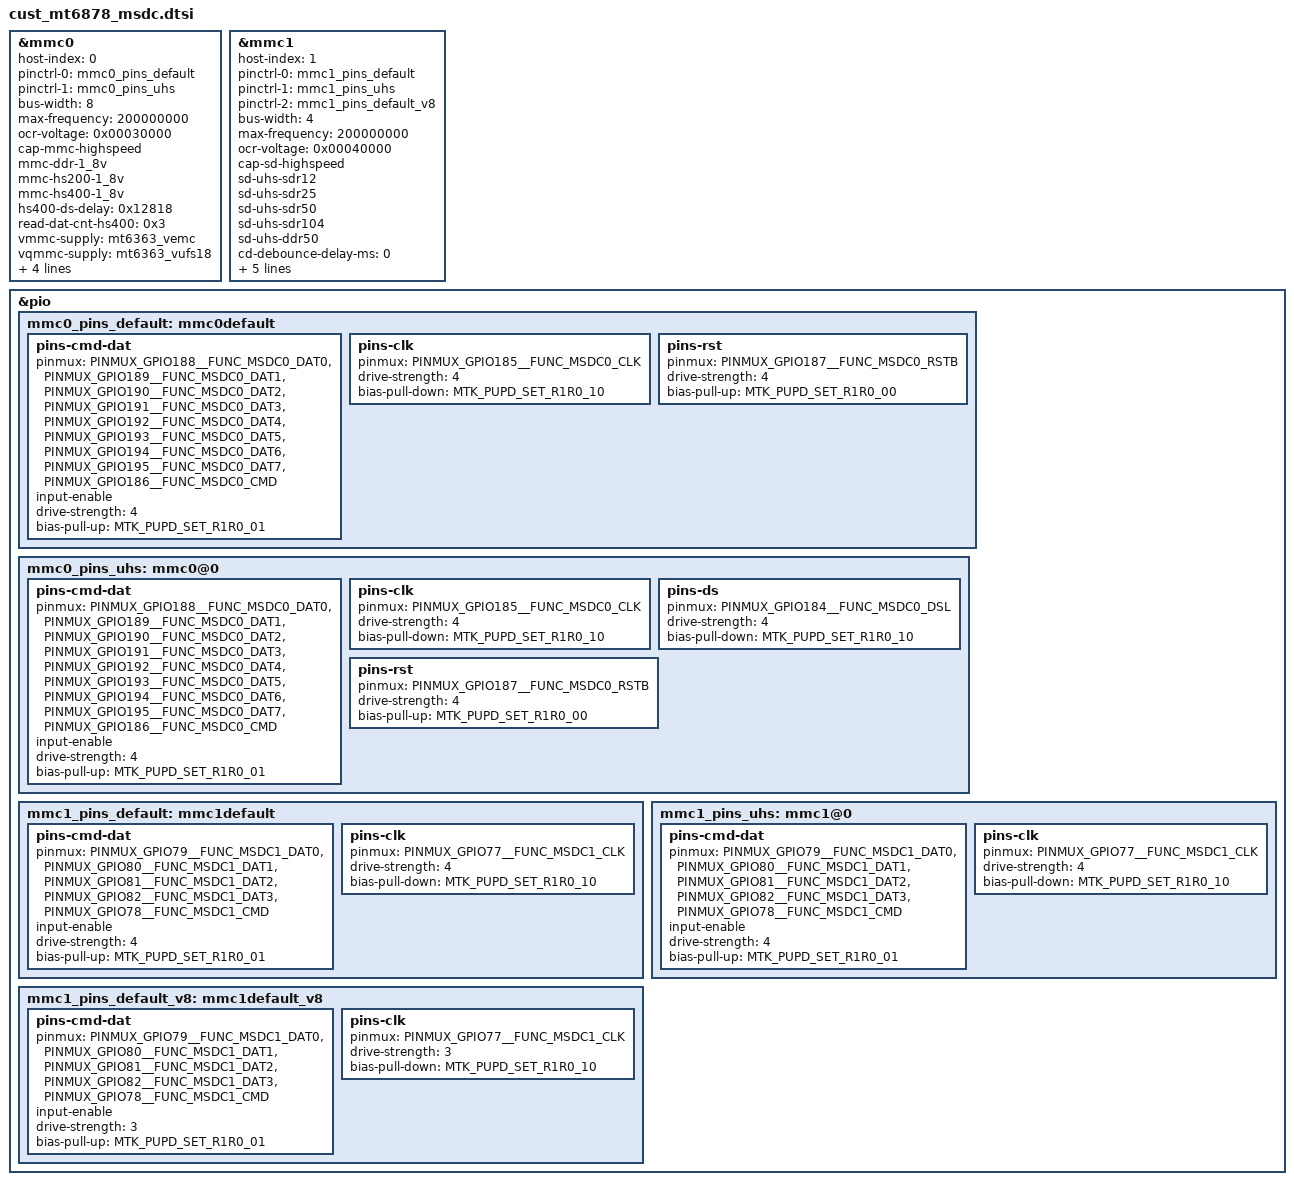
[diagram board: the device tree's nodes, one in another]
// SPDX-License-Identifier: GPL-2.0
/*
 * Copyright (c) 2023 MediaTek Inc.
 */
/********************************************
 * MT6878 MSDC DTSI File
 ********************************************/
#include <dt-bindings/gpio/gpio.h>

&mmc0 {
	host-index = <0>;
	status = "okay";
	pinctrl-names = "default", "state_uhs";
	pinctrl-0 = <&mmc0_pins_default>;
	pinctrl-1 = <&mmc0_pins_uhs>;
	bus-width = <8>;
	max-frequency = <200000000>;
	ocr-voltage = <0x00030000>;
	cap-mmc-highspeed;
	mmc-ddr-1_8v;
	mmc-hs200-1_8v;
	mmc-hs400-1_8v;
	hs400-ds-delay = <0x12818>;
	read-dat-cnt-hs400 = <0x3>;
	vmmc-supply = <&mt6363_vemc>;
	vqmmc-supply = <&mt6363_vufs18>;
	no-sdio;
	no-sd;
	non-removable;
	supports-cqe;
};

&mmc1 {
	host-index = <1>;
	status = "okay";
	pinctrl-names = "default", "state_uhs","default_v8";
	pinctrl-0 = <&mmc1_pins_default>;
	pinctrl-1 = <&mmc1_pins_uhs>;
	pinctrl-2 = <&mmc1_pins_default_v8>;
	bus-width = <4>;
	max-frequency = <200000000>;
	ocr-voltage = <0x00040000>;
	cap-sd-highspeed;
	sd-uhs-sdr12;
	sd-uhs-sdr25;
	sd-uhs-sdr50;
	sd-uhs-sdr104;
	sd-uhs-ddr50;
	cd-debounce-delay-ms = <0>;
	cd-gpios = <&pio 14 GPIO_ACTIVE_HIGH>;
	vmmc-supply = <&mt6369_vmch_eint_low>;
	vqmmc-supply = <&mt6369_vmc>;
	no-mmc;
	no-sdio;
};

&pio {
	mmc0_pins_default: mmc0default {
		pins-cmd-dat {
			pinmux = <PINMUX_GPIO188__FUNC_MSDC0_DAT0>,
				<PINMUX_GPIO189__FUNC_MSDC0_DAT1>,
				<PINMUX_GPIO190__FUNC_MSDC0_DAT2>,
				<PINMUX_GPIO191__FUNC_MSDC0_DAT3>,
				<PINMUX_GPIO192__FUNC_MSDC0_DAT4>,
				<PINMUX_GPIO193__FUNC_MSDC0_DAT5>,
				<PINMUX_GPIO194__FUNC_MSDC0_DAT6>,
				<PINMUX_GPIO195__FUNC_MSDC0_DAT7>,
				<PINMUX_GPIO186__FUNC_MSDC0_CMD>;
			input-enable;
			drive-strength = <4>;
			bias-pull-up = <MTK_PUPD_SET_R1R0_01>;
		};
		pins-clk {
			pinmux = <PINMUX_GPIO185__FUNC_MSDC0_CLK>;
			drive-strength = <4>;
			bias-pull-down = <MTK_PUPD_SET_R1R0_10>;
		};
		pins-rst {
			pinmux = <PINMUX_GPIO187__FUNC_MSDC0_RSTB>;
			drive-strength = <4>;
			bias-pull-up = <MTK_PUPD_SET_R1R0_00>;
		};
	};
	mmc0_pins_uhs: mmc0@0{
		pins-cmd-dat {
			pinmux = <PINMUX_GPIO188__FUNC_MSDC0_DAT0>,
				<PINMUX_GPIO189__FUNC_MSDC0_DAT1>,
				<PINMUX_GPIO190__FUNC_MSDC0_DAT2>,
				<PINMUX_GPIO191__FUNC_MSDC0_DAT3>,
				<PINMUX_GPIO192__FUNC_MSDC0_DAT4>,
				<PINMUX_GPIO193__FUNC_MSDC0_DAT5>,
				<PINMUX_GPIO194__FUNC_MSDC0_DAT6>,
				<PINMUX_GPIO195__FUNC_MSDC0_DAT7>,
				<PINMUX_GPIO186__FUNC_MSDC0_CMD>;
			input-enable;
			drive-strength = <4>;
			bias-pull-up = <MTK_PUPD_SET_R1R0_01>;
		};
		pins-clk {
			pinmux = <PINMUX_GPIO185__FUNC_MSDC0_CLK>;
			drive-strength = <4>;
			bias-pull-down = <MTK_PUPD_SET_R1R0_10>;
		};
		pins-ds {
			pinmux = <PINMUX_GPIO184__FUNC_MSDC0_DSL>;
			drive-strength = <4>;
			bias-pull-down = <MTK_PUPD_SET_R1R0_10>;
		};
		pins-rst {
			pinmux = <PINMUX_GPIO187__FUNC_MSDC0_RSTB>;
			drive-strength = <4>;
			bias-pull-up = <MTK_PUPD_SET_R1R0_00>;
		};
	};
	mmc1_pins_default: mmc1default {
		pins-cmd-dat {
			pinmux = <PINMUX_GPIO79__FUNC_MSDC1_DAT0>,
				<PINMUX_GPIO80__FUNC_MSDC1_DAT1>,
				<PINMUX_GPIO81__FUNC_MSDC1_DAT2>,
				<PINMUX_GPIO82__FUNC_MSDC1_DAT3>,
				<PINMUX_GPIO78__FUNC_MSDC1_CMD>;
			input-enable;
			drive-strength = <4>;
			bias-pull-up = <MTK_PUPD_SET_R1R0_01>;
		};

		pins-clk {
			pinmux = <PINMUX_GPIO77__FUNC_MSDC1_CLK>;
			drive-strength = <4>;
			bias-pull-down = <MTK_PUPD_SET_R1R0_10>;
		};
	};
	mmc1_pins_uhs: mmc1@0{
		pins-cmd-dat {
			pinmux = <PINMUX_GPIO79__FUNC_MSDC1_DAT0>,
				<PINMUX_GPIO80__FUNC_MSDC1_DAT1>,
				<PINMUX_GPIO81__FUNC_MSDC1_DAT2>,
				<PINMUX_GPIO82__FUNC_MSDC1_DAT3>,
				<PINMUX_GPIO78__FUNC_MSDC1_CMD>;
			input-enable;
			drive-strength = <4>;
			bias-pull-up = <MTK_PUPD_SET_R1R0_01>;
		};

		pins-clk {
			pinmux = <PINMUX_GPIO77__FUNC_MSDC1_CLK>;
			drive-strength = <4>;
			bias-pull-down = <MTK_PUPD_SET_R1R0_10>;
		};
	};
        mmc1_pins_default_v8: mmc1default_v8 {  
		pins-cmd-dat {
			pinmux = <PINMUX_GPIO79__FUNC_MSDC1_DAT0>,
				<PINMUX_GPIO80__FUNC_MSDC1_DAT1>,
				<PINMUX_GPIO81__FUNC_MSDC1_DAT2>,
				<PINMUX_GPIO82__FUNC_MSDC1_DAT3>,
				<PINMUX_GPIO78__FUNC_MSDC1_CMD>;
			input-enable;
			drive-strength = <3>;
			bias-pull-up = <MTK_PUPD_SET_R1R0_01>;
		};

		pins-clk {
			pinmux = <PINMUX_GPIO77__FUNC_MSDC1_CLK>;
			drive-strength = <3>;
			bias-pull-down = <MTK_PUPD_SET_R1R0_10>;
		};
	};
};


